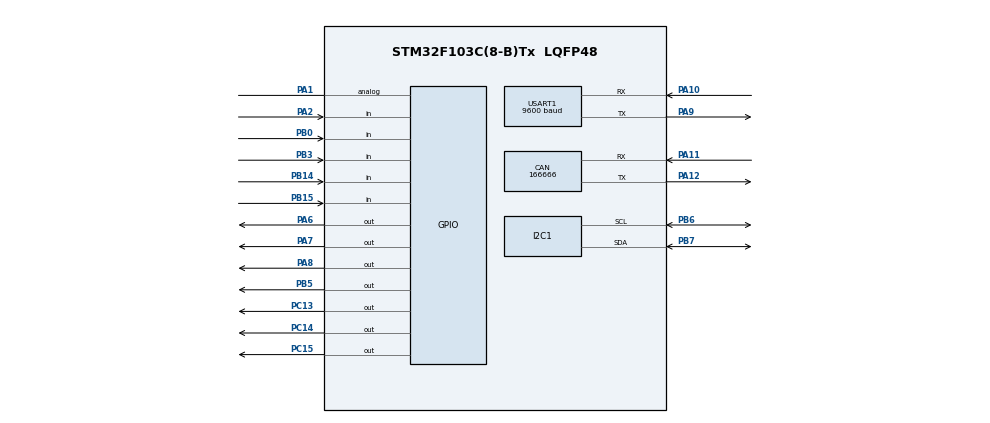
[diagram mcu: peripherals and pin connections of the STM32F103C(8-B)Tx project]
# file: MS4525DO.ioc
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CAN.CalculateBaudRate=166666
CAN.CalculateTimeBit=6000
CAN.CalculateTimeQuantum=2000.0
Mcu.Family=STM32F1
Mcu.Name=STM32F103C(8-B)Tx
Mcu.Package=LQFP48
NVIC.PriorityGroup=NVIC_PRIORITYGROUP_4
PA1.Signal=GPIO_Analog
PA10.Mode=Asynchronous
PA10.Signal=USART1_RX
PA11.Mode=CAN_Activate
PA11.Signal=CAN_RX
PA12.Mode=CAN_Activate
PA12.Signal=CAN_TX
PA13.Mode=Serial_Wire
PA13.Signal=SYS_JTMS-SWDIO
PA14.Mode=Serial_Wire
PA14.Signal=SYS_JTCK-SWCLK
PA2.Signal=GPIO_Input
PA6.Signal=GPIO_Output
PA7.Signal=GPIO_Output
PA8.Signal=GPIO_Output
PA9.Mode=Asynchronous
PA9.Signal=USART1_TX
PB0.Signal=GPIO_Input
PB14.Signal=GPIO_Input
PB15.Signal=GPIO_Input
PB3.Signal=GPIO_Input
PB5.Signal=GPIO_Output
PB6.Mode=I2C
PB6.Signal=I2C1_SCL
PB7.Mode=I2C
PB7.Signal=I2C1_SDA
PC13-TAMPER-RTC.Signal=GPIO_Output
PC14-OSC32_IN.Signal=GPIO_Output
PC15-OSC32_OUT.Signal=GPIO_Output
PD0-OSC_IN.Mode=HSE-External-Oscillator
PD0-OSC_IN.Signal=RCC_OSC_IN
PD1-OSC_OUT.Mode=HSE-External-Oscillator
PD1-OSC_OUT.Signal=RCC_OSC_OUT
ProjectManager.HeapSize=0x200
ProjectManager.StackSize=0x400
ProjectManager.TargetToolchain=STM32CubeIDE
RCC.APB1Freq_Value=8000000
RCC.APB2Freq_Value=8000000
USART1.BaudRate=9600
USART1.VirtualMode=VM_ASYNC
board=custom

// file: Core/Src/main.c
/* USER CODE BEGIN Header */
/**
  ******************************************************************************
  * @file           : main.c
  * @brief          : Main program body
  ******************************************************************************
  * @attention
  *
  * Copyright (c) 2024 STMicroelectronics.
  * All rights reserved.
  *
  * This software is licensed under terms that can be found in the LICENSE file
  * in the root directory of this software component.
  * If no LICENSE file comes with this software, it is provided AS-IS.
  *
  ******************************************************************************
  */
/* USER CODE END Header */
#include "main.h"

/* USER CODE BEGIN Includes */
#include "MS4525DO.h"
/* USER CODE END Includes */

CAN_HandleTypeDef hcan;

I2C_HandleTypeDef hi2c1;

UART_HandleTypeDef huart1;

void SystemClock_Config(void);
static void MX_GPIO_Init(void);
static void MX_I2C1_Init(void);
static void MX_CAN_Init(void);
static void MX_USART1_UART_Init(void);

int main(void)
{

  /* MCU Configuration--------------------------------------------------------*/

  /* Reset of all peripherals, Initializes the Flash interface and the Systick. */
  HAL_Init();

  /* Configure the system clock */
  SystemClock_Config();

  /* Initialize all configured peripherals */
  MX_GPIO_Init();
  MX_I2C1_Init();
  MX_CAN_Init();
  MX_USART1_UART_Init();
  /* USER CODE BEGIN 2 */
  struct MS4525DO_t MS4525DO;
  struct MS4525DO_t *pMS4525DO = &MS4525DO;
  MS4525DO_Initialize(pMS4525DO, &hi2c1);
  /* USER CODE END 2 */

  /* Infinite loop */
  /* USER CODE BEGIN WHILE */
  while (1)
  {
//	  struct MS4525DO_t MS4525DO_data = {.data_is_good = 0, .sensor_status = 0,
//	  .raw = {.pressure = 0, .temperature = 0},
//	  .processed = {.pressure_psi = 0, .temperature_C = 0, .airspeed_ms = 0}}; //default all values to default
//	  struct MS4525DO_t MS4525DO_d;
//	  MS4525DO_data.data_is_good = 0;
//	  MS4525DO_data.sensor_status = 0;
//	  MS4525DO_data.raw.pressure = 0;
//	  MS4525DO_data.raw.temperature = 0;
//	  MS4525DO_data.processed.airspeed_ms = 0;
//	  MS4525DO_data.processed.pressure_psi = 0;
//	  MS4525DO_data.processed.temperature_C = 0;

	  read_MS4525DO(&MS4525DO);

//	  uint8_t s = pMS4525DO_data->sensor_status;
//	  double a = pMS4525DO_data->processed.airspeed_ms;
//	  printf("%u, \r\n", pMS4525DO_data->sensor_status);
//	  printf("%d, \r\n", pMS4525DO_data->processed.airspeed_ms);
    /* USER CODE END WHILE */

  }
}

void SystemClock_Config(void)
{
  RCC_OscInitTypeDef RCC_OscInitStruct = {0};
  RCC_ClkInitTypeDef RCC_ClkInitStruct = {0};

  /** Initializes the RCC Oscillators according to the specified parameters
  * in the RCC_OscInitTypeDef structure.
  */
  RCC_OscInitStruct.OscillatorType = RCC_OSCILLATORTYPE_HSI;
  RCC_OscInitStruct.HSIState = RCC_HSI_ON;
  RCC_OscInitStruct.HSICalibrationValue = RCC_HSICALIBRATION_DEFAULT;
  RCC_OscInitStruct.PLL.PLLState = RCC_PLL_NONE;
  if (HAL_RCC_OscConfig(&RCC_OscInitStruct) != HAL_OK)
  {
    Error_Handler();
  }

  /** Initializes the CPU, AHB and APB buses clocks
  */
  RCC_ClkInitStruct.ClockType = RCC_CLOCKTYPE_HCLK|RCC_CLOCKTYPE_SYSCLK
                              |RCC_CLOCKTYPE_PCLK1|RCC_CLOCKTYPE_PCLK2;
  RCC_ClkInitStruct.SYSCLKSource = RCC_SYSCLKSOURCE_HSI;
  RCC_ClkInitStruct.AHBCLKDivider = RCC_SYSCLK_DIV1;
  RCC_ClkInitStruct.APB1CLKDivider = RCC_HCLK_DIV1;
  RCC_ClkInitStruct.APB2CLKDivider = RCC_HCLK_DIV1;

  if (HAL_RCC_ClockConfig(&RCC_ClkInitStruct, FLASH_LATENCY_0) != HAL_OK)
  {
    Error_Handler();
  }
}

static void MX_CAN_Init(void)
{

  hcan.Instance = CAN1;
  hcan.Init.Prescaler = 16;
  hcan.Init.Mode = CAN_MODE_NORMAL;
  hcan.Init.SyncJumpWidth = CAN_SJW_1TQ;
  hcan.Init.TimeSeg1 = CAN_BS1_1TQ;
  hcan.Init.TimeSeg2 = CAN_BS2_1TQ;
  hcan.Init.TimeTriggeredMode = DISABLE;
  hcan.Init.AutoBusOff = DISABLE;
  hcan.Init.AutoWakeUp = DISABLE;
  hcan.Init.AutoRetransmission = DISABLE;
  hcan.Init.ReceiveFifoLocked = DISABLE;
  hcan.Init.TransmitFifoPriority = DISABLE;
  if (HAL_CAN_Init(&hcan) != HAL_OK)
  {
    Error_Handler();
  }

}

static void MX_I2C1_Init(void)
{

  hi2c1.Instance = I2C1;
  hi2c1.Init.ClockSpeed = 100000;
  hi2c1.Init.DutyCycle = I2C_DUTYCYCLE_2;
  hi2c1.Init.OwnAddress1 = 0;
  hi2c1.Init.AddressingMode = I2C_ADDRESSINGMODE_7BIT;
  hi2c1.Init.DualAddressMode = I2C_DUALADDRESS_DISABLE;
  hi2c1.Init.OwnAddress2 = 0;
  hi2c1.Init.GeneralCallMode = I2C_GENERALCALL_DISABLE;
  hi2c1.Init.NoStretchMode = I2C_NOSTRETCH_DISABLE;
  if (HAL_I2C_Init(&hi2c1) != HAL_OK)
  {
    Error_Handler();
  }

}

static void MX_USART1_UART_Init(void)
{

  huart1.Instance = USART1;
  huart1.Init.BaudRate = 9600;
  huart1.Init.WordLength = UART_WORDLENGTH_8B;
  huart1.Init.StopBits = UART_STOPBITS_1;
  huart1.Init.Parity = UART_PARITY_NONE;
  huart1.Init.Mode = UART_MODE_TX_RX;
  huart1.Init.HwFlowCtl = UART_HWCONTROL_NONE;
  huart1.Init.OverSampling = UART_OVERSAMPLING_16;
  if (HAL_UART_Init(&huart1) != HAL_OK)
  {
    Error_Handler();
  }

}

static void MX_GPIO_Init(void)
{
  GPIO_InitTypeDef GPIO_InitStruct = {0};

  /* GPIO Ports Clock Enable */
  __HAL_RCC_GPIOC_CLK_ENABLE();
  __HAL_RCC_GPIOD_CLK_ENABLE();
  __HAL_RCC_GPIOA_CLK_ENABLE();
  __HAL_RCC_GPIOB_CLK_ENABLE();

  /*Configure GPIO pin Output Level */
  HAL_GPIO_WritePin(GPIOC, GPIO_PIN_13|GPIO_PIN_14|GPIO_PIN_15, GPIO_PIN_RESET);

  /*Configure GPIO pin Output Level */
  HAL_GPIO_WritePin(GPIOA, GPIO_PIN_6|GPIO_PIN_7|GPIO_PIN_8, GPIO_PIN_RESET);

  /*Configure GPIO pin Output Level */
  HAL_GPIO_WritePin(GPIOB, GPIO_PIN_5, GPIO_PIN_RESET);

  /*Configure GPIO pins : PC13 PC14 PC15 */
  GPIO_InitStruct.Pin = GPIO_PIN_13|GPIO_PIN_14|GPIO_PIN_15;
  GPIO_InitStruct.Mode = GPIO_MODE_OUTPUT_PP;
  GPIO_InitStruct.Pull = GPIO_NOPULL;
  GPIO_InitStruct.Speed = GPIO_SPEED_FREQ_LOW;
  HAL_GPIO_Init(GPIOC, &GPIO_InitStruct);

  /*Configure GPIO pin : PA1 */
  GPIO_InitStruct.Pin = GPIO_PIN_1;
  GPIO_InitStruct.Mode = GPIO_MODE_ANALOG;
  HAL_GPIO_Init(GPIOA, &GPIO_InitStruct);

  /*Configure GPIO pin : PA2 */
  GPIO_InitStruct.Pin = GPIO_PIN_2;
  GPIO_InitStruct.Mode = GPIO_MODE_INPUT;
  GPIO_InitStruct.Pull = GPIO_NOPULL;
  HAL_GPIO_Init(GPIOA, &GPIO_InitStruct);

  /*Configure GPIO pins : PA6 PA7 PA8 */
  GPIO_InitStruct.Pin = GPIO_PIN_6|GPIO_PIN_7|GPIO_PIN_8;
  GPIO_InitStruct.Mode = GPIO_MODE_OUTPUT_PP;
  GPIO_InitStruct.Pull = GPIO_NOPULL;
  GPIO_InitStruct.Speed = GPIO_SPEED_FREQ_LOW;
  HAL_GPIO_Init(GPIOA, &GPIO_InitStruct);

  /*Configure GPIO pins : PB0 PB14 PB15 PB3 */
  GPIO_InitStruct.Pin = GPIO_PIN_0|GPIO_PIN_14|GPIO_PIN_15|GPIO_PIN_3;
  GPIO_InitStruct.Mode = GPIO_MODE_INPUT;
  GPIO_InitStruct.Pull = GPIO_NOPULL;
  HAL_GPIO_Init(GPIOB, &GPIO_InitStruct);

  /*Configure GPIO pin : PB5 */
  GPIO_InitStruct.Pin = GPIO_PIN_5;
  GPIO_InitStruct.Mode = GPIO_MODE_OUTPUT_PP;
  GPIO_InitStruct.Pull = GPIO_NOPULL;
  GPIO_InitStruct.Speed = GPIO_SPEED_FREQ_LOW;
  HAL_GPIO_Init(GPIOB, &GPIO_InitStruct);

}

void Error_Handler(void)
{
  /* USER CODE BEGIN Error_Handler_Debug */
  /* User can add his own implementation to report the HAL error return state */
  __disable_irq();
  while (1)
  {
	  HAL_GPIO_WritePin(GPIOA, GPIO_PIN_6, 1);
	      HAL_Delay(500);
	      HAL_GPIO_WritePin(GPIOA, GPIO_PIN_6, 0);
	      HAL_Delay(500);
	 break;
  }
  /* USER CODE END Error_Handler_Debug */
}
